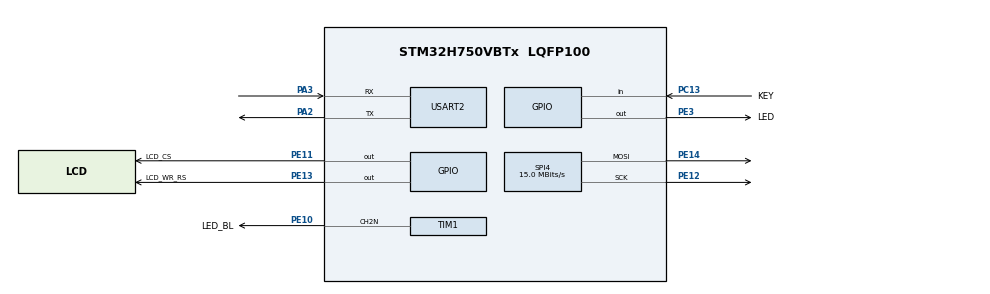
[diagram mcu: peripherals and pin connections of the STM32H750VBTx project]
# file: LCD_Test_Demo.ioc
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CORTEX_M7.AccessPermission_S-Cortex_Memory_Protection_Unit_Region1_Settings_S=MPU_REGION_FULL_ACCESS
CORTEX_M7.BaseAddress_S-Cortex_Memory_Protection_Unit_Region1_Settings_S=QSPI_BASE
CORTEX_M7.BaseAddress_Spec=QSPI_BASE
CORTEX_M7.CPU_DCache=Enabled
CORTEX_M7.CPU_ICache=Enabled
CORTEX_M7.Enable_S-Cortex_Memory_Protection_Unit_Region1_Settings_S=MPU_REGION_ENABLE
CORTEX_M7.IsBufferable_S-Cortex_Memory_Protection_Unit_Region1_Settings_S=MPU_ACCESS_BUFFERABLE
CORTEX_M7.IsCacheable_S-Cortex_Memory_Protection_Unit_Region1_Settings_S=MPU_ACCESS_CACHEABLE
CORTEX_M7.IsShareable_S-Cortex_Memory_Protection_Unit_Region1_Settings_S=MPU_ACCESS_SHAREABLE
CORTEX_M7.IsShareable_Spec=MPU_ACCESS_NOT_SHAREABLE
CORTEX_M7.Size_S-Cortex_Memory_Protection_Unit_Region1_Settings_S=MPU_REGION_SIZE_8MB
CORTEX_M7.Size_Spec=MPU_REGION_SIZE_256MB
CORTEX_M7.SubRegionDisable_S-Cortex_Memory_Protection_Unit_Region1_Settings_S=0x00
CORTEX_M7.SubRegionDisable_Spec=0x00
CORTEX_M7.TypeExtField_S-Cortex_Memory_Protection_Unit_Region1_Settings_S=MPU_TEX_LEVEL1
CORTEX_M7.TypeExtField_Spec=MPU_TEX_LEVEL1
CORTEX_M7.default_mode_Activation=1
Dma.Request0=SPI4_TX
Dma.Request1=USART2_TX
Dma.Request2=USART2_RX
Dma.SPI4_TX.0.Direction=DMA_MEMORY_TO_PERIPH
Dma.SPI4_TX.0.EventEnable=DISABLE
Dma.SPI4_TX.0.FIFOMode=DMA_FIFOMODE_DISABLE
Dma.SPI4_TX.0.Instance=DMA1_Stream0
Dma.SPI4_TX.0.MemDataAlignment=DMA_MDATAALIGN_BYTE
Dma.SPI4_TX.0.MemInc=DMA_MINC_ENABLE
Dma.SPI4_TX.0.Mode=DMA_NORMAL
Dma.SPI4_TX.0.PeriphDataAlignment=DMA_PDATAALIGN_BYTE
Dma.SPI4_TX.0.PeriphInc=DMA_PINC_DISABLE
Dma.SPI4_TX.0.Polarity=HAL_DMAMUX_REQ_GEN_RISING
Dma.SPI4_TX.0.Priority=DMA_PRIORITY_LOW
Dma.SPI4_TX.0.RequestNumber=1
Dma.SPI4_TX.0.SignalID=NONE
Dma.SPI4_TX.0.SyncEnable=DISABLE
Dma.SPI4_TX.0.SyncPolarity=HAL_DMAMUX_SYNC_NO_EVENT
Dma.SPI4_TX.0.SyncRequestNumber=1
Dma.SPI4_TX.0.SyncSignalID=NONE
Dma.USART2_RX.2.Direction=DMA_PERIPH_TO_MEMORY
Dma.USART2_RX.2.EventEnable=DISABLE
Dma.USART2_RX.2.FIFOMode=DMA_FIFOMODE_DISABLE
Dma.USART2_RX.2.Instance=DMA1_Stream2
Dma.USART2_RX.2.MemDataAlignment=DMA_MDATAALIGN_BYTE
Dma.USART2_RX.2.MemInc=DMA_MINC_ENABLE
Dma.USART2_RX.2.Mode=DMA_NORMAL
Dma.USART2_RX.2.PeriphDataAlignment=DMA_PDATAALIGN_BYTE
Dma.USART2_RX.2.PeriphInc=DMA_PINC_DISABLE
Dma.USART2_RX.2.Polarity=HAL_DMAMUX_REQ_GEN_RISING
Dma.USART2_RX.2.Priority=DMA_PRIORITY_MEDIUM
Dma.USART2_RX.2.RequestNumber=1
Dma.USART2_RX.2.SignalID=NONE
Dma.USART2_RX.2.SyncEnable=DISABLE
Dma.USART2_RX.2.SyncPolarity=HAL_DMAMUX_SYNC_NO_EVENT
Dma.USART2_RX.2.SyncRequestNumber=1
Dma.USART2_RX.2.SyncSignalID=NONE
Dma.USART2_TX.1.Direction=DMA_MEMORY_TO_PERIPH
Dma.USART2_TX.1.EventEnable=DISABLE
Dma.USART2_TX.1.FIFOMode=DMA_FIFOMODE_DISABLE
Dma.USART2_TX.1.Instance=DMA1_Stream1
Dma.USART2_TX.1.MemDataAlignment=DMA_MDATAALIGN_BYTE
Dma.USART2_TX.1.MemInc=DMA_MINC_ENABLE
Dma.USART2_TX.1.Mode=DMA_NORMAL
Dma.USART2_TX.1.PeriphDataAlignment=DMA_PDATAALIGN_BYTE
Dma.USART2_TX.1.PeriphInc=DMA_PINC_DISABLE
Dma.USART2_TX.1.Polarity=HAL_DMAMUX_REQ_GEN_RISING
Dma.USART2_TX.1.Priority=DMA_PRIORITY_MEDIUM
Dma.USART2_TX.1.RequestNumber=1
Dma.USART2_TX.1.SignalID=NONE
Dma.USART2_TX.1.SyncEnable=DISABLE
Dma.USART2_TX.1.SyncPolarity=HAL_DMAMUX_SYNC_NO_EVENT
Dma.USART2_TX.1.SyncRequestNumber=1
Dma.USART2_TX.1.SyncSignalID=NONE
Mcu.Family=STM32H7
Mcu.Name=STM32H750VBTx
Mcu.Package=LQFP100
NVIC.DMA1_Stream0_IRQn=true\:0\:0\:false\:false\:true\:false\:true\:true
NVIC.DMA1_Stream1_IRQn=true\:0\:0\:false\:false\:true\:false\:true\:true
NVIC.DMA1_Stream2_IRQn=true\:0\:0\:false\:false\:true\:false\:true\:true
NVIC.PriorityGroup=NVIC_PRIORITYGROUP_4
NVIC.SPI4_IRQn=true\:0\:0\:false\:false\:true\:false\:true\:true
NVIC.USART2_IRQn=true\:0\:0\:false\:false\:true\:true\:true\:true
PA13\ (JTMS/SWDIO).Mode=Serial_Wire
PA13\ (JTMS/SWDIO).Signal=DEBUG_JTMS-SWDIO
PA14\ (JTCK/SWCLK).Mode=Serial_Wire
PA14\ (JTCK/SWCLK).Signal=DEBUG_JTCK-SWCLK
PA2.Mode=Asynchronous
PA2.Signal=USART2_TX
PA3.Mode=Asynchronous
PA3.Signal=USART2_RX
PC13.GPIO_Label=KEY
PC13.GPIO_PuPd=GPIO_PULLDOWN
PC13.Signal=GPIO_Input
PC14-OSC32_IN\ (OSC32_IN).Mode=LSE-External-Oscillator
PC14-OSC32_IN\ (OSC32_IN).Signal=RCC_OSC32_IN
PC15-OSC32_OUT\ (OSC32_OUT).Mode=LSE-External-Oscillator
PC15-OSC32_OUT\ (OSC32_OUT).Signal=RCC_OSC32_OUT
PE10.GPIO_Label=LED_BL
PE10.Mode=PWM Generation2 CH2N
PE10.Signal=TIM1_CH2N
PE11.GPIO_Label=LCD_CS
PE11.Signal=GPIO_Output
PE12.Mode=TX_Only_Simplex_Unidirect_Master
PE12.Signal=SPI4_SCK
PE13.GPIO_Label=LCD_WR_RS
PE13.Signal=GPIO_Output
PE14.Mode=TX_Only_Simplex_Unidirect_Master
PE14.Signal=SPI4_MOSI
PE3.GPIO_Label=LED
PE3.Signal=GPIO_Output
PH0-OSC_IN\ (PH0).Mode=HSE-External-Oscillator
PH0-OSC_IN\ (PH0).Signal=RCC_OSC_IN
PH1-OSC_OUT\ (PH1).Mode=HSE-External-Oscillator
PH1-OSC_OUT\ (PH1).Signal=RCC_OSC_OUT
ProjectManager.HeapSize=0x200
ProjectManager.StackSize=0x400
ProjectManager.TargetToolchain=Makefile
RCC.ADCFreq_Value=128000000
RCC.APB1Freq_Value=120000000
RCC.APB2Freq_Value=120000000
RCC.APB3Freq_Value=120000000
RCC.APB4Freq_Value=120000000
RCC.CortexFreq_Value=480000000
RCC.D1PPRE=RCC_APB3_DIV2
RCC.D2PPRE1=RCC_APB1_DIV2
RCC.D2PPRE2=RCC_APB2_DIV2
RCC.D3PPRE=RCC_APB4_DIV2
RCC.DIVM1=4
RCC.DIVN1=60
RCC.DIVN2=128
RCC.DIVN3=128
RCC.HCLKFreq_Value=240000000
RCC.HPRE=RCC_HCLK_DIV2
RCC.PLL2FRACN=0
RCC.PLL3FRACN=0
RCC.PLLFRACN=0
RCC.SYSCLKFreq_VALUE=480000000
RCC.SYSCLKSource=RCC_SYSCLKSOURCE_PLLCLK
RCC.USBFreq_Value=480000000
SPI4.BaudRatePrescaler=SPI_BAUDRATEPRESCALER_8
SPI4.CalculateBaudRate=15.0 MBits/s
SPI4.DataSize=SPI_DATASIZE_8BIT
SPI4.Direction=SPI_DIRECTION_2LINES_TXONLY
SPI4.Mode=SPI_MODE_MASTER
SPI4.VirtualType=VM_MASTER
TIM1.Channel-PWM\ Generation2\ CH2N=TIM_CHANNEL_2
TIM1.OCNPolarity_2=TIM_OCNPOLARITY_LOW
TIM1.Period=1000-1
TIM1.Prescaler=12-1
USART2.Parity=PARITY_NONE
USART2.VirtualMode-Asynchronous=VM_ASYNC
VP_MEMORYMAP_VS_MEMORYMAP.Mode=CurAppReg
board=custom

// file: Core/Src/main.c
/* USER CODE BEGIN Header */
/**
 ******************************************************************************
 * @file           : main.c
 * @brief          : Main program body
 ******************************************************************************
 * @attention
 *
 * Copyright (c) 2025 STMicroelectronics.
 * All rights reserved.
 *
 * This software is licensed under terms that can be found in the LICENSE file
 * in the root directory of this software component.
 * If no LICENSE file comes with this software, it is provided AS-IS.
 *
 ******************************************************************************
 */
/* USER CODE END Header */
#include "main.h"
#include "dma.h"
#include "memorymap.h"
#include "spi.h"
#include "tim.h"
#include "usart.h"
#include "gpio.h"

/* USER CODE BEGIN PV */
uint8_t text_buff[32] = {0};
/* USER CODE END PV */

void SystemClock_Config(void);
static void MPU_Config(void);

int main(void)
{

	/* USER CODE BEGIN 1 */
	SCB->CACR |= 1 << 2;
	/* USER CODE END 1 */

	/* MPU Configuration--------------------------------------------------------*/
	MPU_Config();

	/* Enable the CPU Cache */

	/* Enable I-Cache---------------------------------------------------------*/
	SCB_EnableICache();

	/* Enable D-Cache---------------------------------------------------------*/
	SCB_EnableDCache();

	/* MCU Configuration--------------------------------------------------------*/

	/* Reset of all peripherals, Initializes the Flash interface and the Systick. */
	HAL_Init();

	/* USER CODE BEGIN Init */
	// uint8_t text[32] = {0};
	/* USER CODE END Init */

	/* Configure the system clock */
	SystemClock_Config();

	/* Initialize all configured peripherals */
	MX_GPIO_Init();
	MX_DMA_Init();
	MX_SPI4_Init();
	MX_TIM1_Init();
	MX_USART2_UART_Init();
	/* USER CODE BEGIN 2 */
	LCD_Init();
	/* USER CODE END 2 */

	/* Infinite loop */
	/* USER CODE BEGIN WHILE */
	LCD_Light(100, 200);
	ST7735_LCD_Driver.FillRect(&st7735_pObj, 0, 0, ST7735Ctx.Width, ST7735Ctx.Height, BLACK);
	LCD_ShowString(4, 4, ST7735Ctx.Width, 16, 12, (uint8_t *)"LCD IS READY.");
	HAL_UART_Transmit_DMA(&huart2, (uint8_t *)"usart test ok\n", sizeof("usart test ok"));

	HAL_Delay(1000);
	ST7735_LCD_Driver.FillRect(&st7735_pObj, 0, 0, ST7735Ctx.Width, ST7735Ctx.Height, BLACK);

		while (1) {
		HAL_GPIO_TogglePin(LED_GPIO_Port, LED_Pin);
		HAL_Delay(500);
		/* USER CODE END WHILE */

	}
}

void SystemClock_Config(void)
{
	RCC_OscInitTypeDef RCC_OscInitStruct = {0};
	RCC_ClkInitTypeDef RCC_ClkInitStruct = {0};

	/** Supply configuration update enable
	 */
	HAL_PWREx_ConfigSupply(PWR_LDO_SUPPLY);

	/** Configure the main internal regulator output voltage
	 */
	__HAL_PWR_VOLTAGESCALING_CONFIG(PWR_REGULATOR_VOLTAGE_SCALE0);

	while (!__HAL_PWR_GET_FLAG(PWR_FLAG_VOSRDY)) {}

	/** Initializes the RCC Oscillators according to the specified parameters
	 * in the RCC_OscInitTypeDef structure.
	 */
	RCC_OscInitStruct.OscillatorType	  = RCC_OSCILLATORTYPE_HSI;
	RCC_OscInitStruct.HSIState			  = RCC_HSI_DIV1;
	RCC_OscInitStruct.HSICalibrationValue = RCC_HSICALIBRATION_DEFAULT;
	RCC_OscInitStruct.PLL.PLLState		  = RCC_PLL_ON;
	RCC_OscInitStruct.PLL.PLLSource		  = RCC_PLLSOURCE_HSI;
	RCC_OscInitStruct.PLL.PLLM			  = 4;
	RCC_OscInitStruct.PLL.PLLN			  = 60;
	RCC_OscInitStruct.PLL.PLLP			  = 2;
	RCC_OscInitStruct.PLL.PLLQ			  = 2;
	RCC_OscInitStruct.PLL.PLLR			  = 2;
	RCC_OscInitStruct.PLL.PLLRGE		  = RCC_PLL1VCIRANGE_3;
	RCC_OscInitStruct.PLL.PLLVCOSEL		  = RCC_PLL1VCOWIDE;
	RCC_OscInitStruct.PLL.PLLFRACN		  = 0;
	if (HAL_RCC_OscConfig(&RCC_OscInitStruct) != HAL_OK) {
		Error_Handler();
	}

	/** Initializes the CPU, AHB and APB buses clocks
	 */
	RCC_ClkInitStruct.ClockType		 = RCC_CLOCKTYPE_HCLK | RCC_CLOCKTYPE_SYSCLK | RCC_CLOCKTYPE_PCLK1 | RCC_CLOCKTYPE_PCLK2 | RCC_CLOCKTYPE_D3PCLK1 | RCC_CLOCKTYPE_D1PCLK1;
	RCC_ClkInitStruct.SYSCLKSource	 = RCC_SYSCLKSOURCE_PLLCLK;
	RCC_ClkInitStruct.SYSCLKDivider	 = RCC_SYSCLK_DIV1;
	RCC_ClkInitStruct.AHBCLKDivider	 = RCC_HCLK_DIV2;
	RCC_ClkInitStruct.APB3CLKDivider = RCC_APB3_DIV2;
	RCC_ClkInitStruct.APB1CLKDivider = RCC_APB1_DIV2;
	RCC_ClkInitStruct.APB2CLKDivider = RCC_APB2_DIV2;
	RCC_ClkInitStruct.APB4CLKDivider = RCC_APB4_DIV2;

	if (HAL_RCC_ClockConfig(&RCC_ClkInitStruct, FLASH_LATENCY_4) != HAL_OK) {
		Error_Handler();
	}
}

/* MPU Configuration */

void MPU_Config(void)
{
	MPU_Region_InitTypeDef MPU_InitStruct = {0};

	/* Disables the MPU */
	HAL_MPU_Disable();

	/** Initializes and configures the Region and the memory to be protected
	 */
	MPU_InitStruct.Enable			= MPU_REGION_ENABLE;
	MPU_InitStruct.Number			= MPU_REGION_NUMBER0;
	MPU_InitStruct.BaseAddress		= QSPI_BASE;
	MPU_InitStruct.Size				= MPU_REGION_SIZE_256MB;
	MPU_InitStruct.SubRegionDisable = 0x00;
	MPU_InitStruct.TypeExtField		= MPU_TEX_LEVEL1;
	MPU_InitStruct.AccessPermission = MPU_REGION_NO_ACCESS;
	MPU_InitStruct.DisableExec		= MPU_INSTRUCTION_ACCESS_DISABLE;
	MPU_InitStruct.IsShareable		= MPU_ACCESS_NOT_SHAREABLE;
	MPU_InitStruct.IsCacheable		= MPU_ACCESS_NOT_CACHEABLE;
	MPU_InitStruct.IsBufferable		= MPU_ACCESS_NOT_BUFFERABLE;

	HAL_MPU_ConfigRegion(&MPU_InitStruct);

	/** Initializes and configures the Region and the memory to be protected
	 */
	MPU_InitStruct.Number			= MPU_REGION_NUMBER1;
	MPU_InitStruct.Size				= MPU_REGION_SIZE_8MB;
	MPU_InitStruct.AccessPermission = MPU_REGION_FULL_ACCESS;
	MPU_InitStruct.DisableExec		= MPU_INSTRUCTION_ACCESS_ENABLE;
	MPU_InitStruct.IsShareable		= MPU_ACCESS_SHAREABLE;
	MPU_InitStruct.IsCacheable		= MPU_ACCESS_CACHEABLE;
	MPU_InitStruct.IsBufferable		= MPU_ACCESS_BUFFERABLE;

	HAL_MPU_ConfigRegion(&MPU_InitStruct);
	/* Enables the MPU */
	HAL_MPU_Enable(MPU_PRIVILEGED_DEFAULT);
}

void Error_Handler(void)
{
	__disable_irq();
	while (1) {
	}
}
